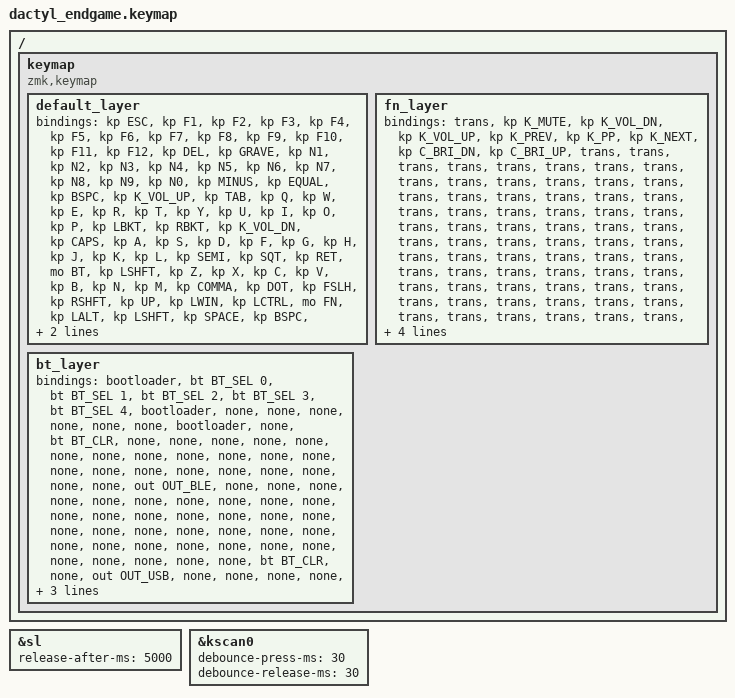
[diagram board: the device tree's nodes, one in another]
#include <behaviors.dtsi>
#include <dt-bindings/zmk/keys.h>
#include <dt-bindings/zmk/bt.h>
#include <dt-bindings/zmk/outputs.h>

#define DEFAULT 0
#define FN 1
#define BT 2


&sl {
    release-after-ms = <5000>;
};

&kscan0 {
    debounce-press-ms = <30>;
    debounce-release-ms = <30>;
};

/ {
    keymap {
        compatible = "zmk,keymap";

        default_layer {
            bindings = <
   &kp ESC &kp F1    &kp F2    &kp F3   &kp F4    &kp F5    &kp F6        &kp F7    &kp F8    &kp F9    &kp F10   &kp F11    &kp F12   &kp DEL
   &kp GRAVE      &kp N1    &kp N2    &kp N3   &kp N4    &kp N5    &kp N6        &kp N7    &kp N8    &kp N9    &kp N0    &kp MINUS  &kp EQUAL &kp BSPC
   &kp K_VOL_UP   &kp TAB   &kp Q     &kp W    &kp E     &kp R     &kp T         &kp Y     &kp U     &kp I     &kp O     &kp P      &kp LBKT  &kp RBKT
   &kp K_VOL_DN &kp CAPS &kp A     &kp S    &kp D     &kp F     &kp G         &kp H     &kp J     &kp K     &kp L     &kp SEMI   &kp SQT   &kp RET
   &mo BT        &kp LSHFT &kp Z     &kp X    &kp C     &kp V     &kp B         &kp N     &kp M     &kp COMMA &kp DOT   &kp FSLH   &kp RSHFT &kp UP
   &kp LWIN       &kp LCTRL &mo FN    &kp LALT &kp LSHFT &kp SPACE &kp BSPC      &kp BSPC   &kp SPACE &kp RSHFT &kp BSLH  &kp LEFT   &kp RIGHT  &kp DOWN
            >;
        };

        fn_layer {
            bindings = <
   &trans       &kp K_MUTE &kp K_VOL_DN &kp K_VOL_UP &kp K_PREV &kp K_PP &kp K_NEXT   &kp C_BRI_DN &kp C_BRI_UP        &trans     &trans      &trans    &trans
   &trans           &trans    &trans     &trans    &trans     &trans     &trans         &trans     &trans     &trans     &trans     &trans      &trans    &trans
   &trans           &trans    &trans     &trans    &trans     &trans     &trans         &trans     &trans     &trans     &trans     &trans      &trans    &trans
   &trans           &trans    &trans     &trans    &trans     &trans     &trans         &trans     &trans     &trans     &trans     &trans      &trans    &trans
   &trans           &trans    &trans     &trans    &trans     &trans     &trans         &trans     &trans     &trans     &trans     &trans      &trans    &trans
   &trans           &trans    &trans     &trans    &trans     &trans     &trans         &trans     &trans     &trans     &trans     &trans      &trans    &trans
   &trans           &trans    &trans     &trans    &trans     &trans     &trans         &trans     &trans     &trans     &trans     &trans      &trans    &trans
            >;
        };

        bt_layer {
            bindings = <
   &bootloader &bt BT_SEL 0 &bt BT_SEL 1 &bt BT_SEL 2 &bt BT_SEL 3 &bt BT_SEL 4 &bootloader &none     &none     &none     &none     &none      &none    &bootloader
   &none           &bt BT_CLR &none     &none    &none     &none     &none         &none     &none     &none     &none     &none      &none    &none
   &none           &none    &none     &none    &none     &none     &none         &none     &none     &out OUT_BLE &none     &none      &none    &none
   &none           &none    &none     &none    &none     &none     &none         &none     &none     &none     &none     &none      &none    &none
   &none           &none    &none     &none    &none     &none     &none         &none     &none     &none     &none     &none      &none    &none
   &none           &none    &none     &none    &bt BT_CLR &none     &out OUT_USB &none     &none     &none     &none     &none      &none    &none
   &none           &none    &none     &none    &none     &none     &none         &none     &none     &none     &none     &none      &none    &none
            >;
        };



    };
};
